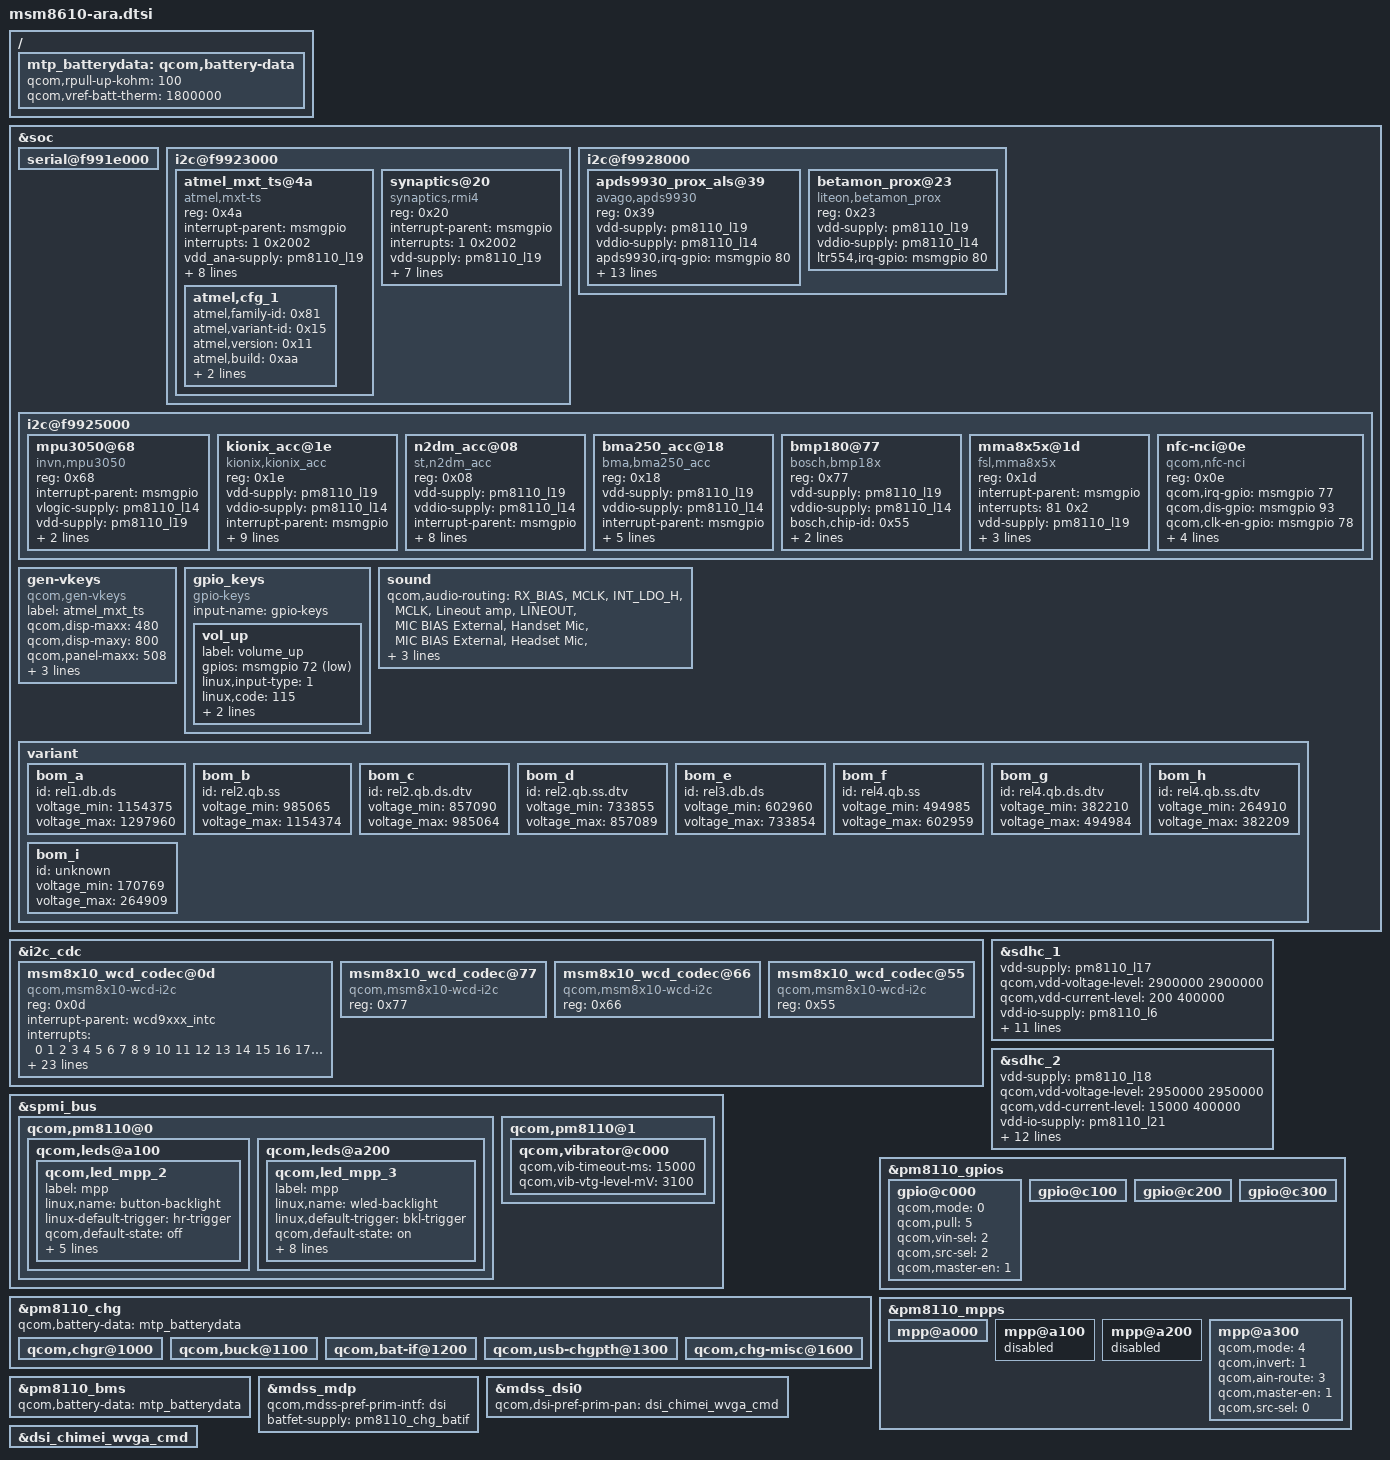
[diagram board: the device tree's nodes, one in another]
/* Copyright (c) 2013-2014, The Linux Foundation. All rights reserved.
 *
 * This program is free software; you can redistribute it and/or modify
 * it under the terms of the GNU General Public License version 2 and
 * only version 2 as published by the Free Software Foundation.
 *
 * This program is distributed in the hope that it will be useful,
 * but WITHOUT ANY WARRANTY; without even the implied warranty of
 * MERCHANTABILITY or FITNESS FOR A PARTICULAR PURPOSE.  See the
 * GNU General Public License for more details.
 */

&soc {
	serial@f991e000 {
		status = "ok";
	};

	i2c@f9923000{
		atmel_mxt_ts@4a {
		compatible = "atmel,mxt-ts";
		reg = <0x4a>;
		interrupt-parent = <&msmgpio>;
		interrupts = <1 0x2002>;
		vdd_ana-supply = <&pm8110_l19>;
		vcc_i2c-supply = <&pm8110_l14>;
		atmel,reset-gpio = <&msmgpio 0 0x00>;
		atmel,irq-gpio = <&msmgpio 1 0x00>;
		atmel,panel-coords = <0 0 508 880>;
		atmel,display-coords = <0 0 480 800>;
		atmel,i2c-pull-up;
		atmel,no-force-update;
		atmel,no-lpm-support;
		atmel,cfg_1 {
			atmel,family-id = <0x81>;
			atmel,variant-id = <0x15>;
			atmel,version = <0x11>;
			atmel,build = <0xaa>;
			atmel,config = [
				/* Object 6, Instance = 0 */
				00 00 00 00 00 00
				/* Object 38, Instance = 0 */
				1d 13 00 17 01 0e 00 00
				/* Object 7, Instance = 0 */
				20 0a 32
				/* Object 8, Instance = 0 */
				19 00 14 14 00 00 ff 00 00 00
				/* Object 9, Instance = 0 */
				83 00 00 13 0b 00 20 32 01 03
				00 0a 05 30 05 05 0a 00 70 03
				fc 01 04 2f f8 dc 00 00 40 00
				00 0a 00 00 02
				/* Object 18, Instance = 0 */
				00 00
				/* Object 19, Instance = 0 */
				00 00 00 00 00 00
				/* Object 25, Instance = 0 */
				03 00 18 79 a8 61
				/* Object 58, Instance = 0 */
				00 00 00 00 00 00 00 00 00 00
				00
				/* Object 42, Instance = 0 */
				03 19 1e 14 80 05 05 00
				/* Object 46, Instance = 0 */
				04 03 08 10 00 00 00 00 00
				/* Object 47, Instance = 0 */
				00 00 00 00 00 00 00 00 00 00
				/* Object 48, Instance = 0 */
				1d c0 22 00 00 00 00 00 00 00
				20 19 00 06 06 00 00 64 04 40
				00 00 00 05 00 2a 00 00 00 19
				34 0c 00 00 00 00 00 00 00 00
				00 00 00 00 00 00 00 00 00 00
				00 00 00 00
				/* Object 55, Instance = 0 */
				00 00 00 00
				];
			};
		};

		synaptics@20 {
			compatible = "synaptics,rmi4";
			reg = <0x20>;
			interrupt-parent = <&msmgpio>;
			interrupts = <1 0x2002>;
			vdd-supply = <&pm8110_l19>;
			vcc_i2c-supply = <&pm8110_l14>;
			synaptics,reset-gpio = <&msmgpio 0 0x00>;
			synaptics,irq-gpio = <&msmgpio 1 0x2008>;
			synaptics,button-map = <139 102 158>;
			synaptics,i2c-pull-up;
			synaptics,power-down;
			synaptics,disable-gpios;
		};
	};

	i2c@f9928000 {
        apds9930_prox_als@39 {
            reg = <0x39>;
            compatible = "avago,apds9930";
            vdd-supply = <&pm8110_l19>;
            vddio-supply = <&pm8110_l14>;
            apds9930,irq-gpio = <&msmgpio 80 0>;
            apds9930,ps_detection_threshold = <708>;
            apds9930,ps_hsythresis_threshold = <458>;
            apds9930,ps_pulse_number = <3>;
            apds9930,ps_pdrive_ma = <0x40>;
            apds9930,ps_pgain = <0x08>;
            apds9930,ps_poffset = <0>;
            apds9930,als_threshold_hsytersis = <20>;
            apds9930,als_use_irq_in_idle = <1>;
            apds9930,als_ga = <2200>;
            apds9930,als_coe_b = <186>;
            apds9930,als_coe_c = <82>;
            apds9930,als_coe_d = <116>;
            apds9930,als_df = <52>;
        };
    };

	i2c@f9925000 {
		mpu3050@68 {
			#address-cells = <1>;
			#size-cells = <0>;
			status = "okay";
			reg = <0x68>;
			compatible = "invn,mpu3050";
			interrupt-parent = <&msmgpio>;
			vlogic-supply = <&pm8110_l14>;
			vdd-supply = <&pm8110_l19>;
			invn,gpio-en = <&pm8110_gpios 2 0x2>;
			invn,poll-interval = <200>;
		};

                kionix_acc@1e {
                        reg = <0x1e>;
                        compatible = "kionix,kionix_acc";
                        vdd-supply = <&pm8110_l19>;
                        vddio-supply = <&pm8110_l14>;
                        interrupt-parent = <&msmgpio>;
                        interrupts = <81 0x2>;
                        kionix_acc,min_interval = <0x5>;
                        kionix_acc,poll_interval = <200>;
                        kionix_acc,accel_direction = <6>;
                        kionix_acc,accel_irq_use_ddtap = <1>;
                        kionix_acc,accel_res = <3>;
                        kionix_acc,accel_g_range = <0>;
                        kionix_acc,accel_tap_z_direction = <1>;
                        kionix_acc,accel_dtap_z_direction = <1>;
                };

                n2dm_acc@08 {
                        reg = <0x08>;
                        compatible = "st,n2dm_acc";
                        vdd-supply = <&pm8110_l19>;
                        vddio-supply = <&pm8110_l14>;
                        interrupt-parent = <&msmgpio>;
                        interrupts = <81 0x2>;
                        n2dm_acc,min_interval = <0x5>;
                        n2dm_acc,poll_interval = <200>;
                        n2dm_acc,accel_direction = <6>;
                        n2dm_acc,accel_irq_use_ddtap = <1>;
                        n2dm_acc,accel_g_range = <0>;
                        n2dm_acc,accel_tap_z_direction = <1>;
                        n2dm_acc,accel_dtap_z_direction = <1>;
                };

                bma250_acc@18 {
                        reg = <0x18>;
                        compatible = "bma,bma250_acc";
                        vdd-supply = <&pm8110_l19>;
                        vddio-supply = <&pm8110_l14>;
                        interrupt-parent = <&msmgpio>;
                        interrupts = <81 0x2>;
                        bma250_acc,min_interval = <0x5>;
                        bma250_acc,poll_interval = <200>;
                        bma250_acc,accel_direction = <6>;
                        bma250_acc,accel_g_range = <3>;
                }; 
		bmp180@77 {
			reg = <0x77>;
			compatible = "bosch,bmp18x";
			vdd-supply = <&pm8110_l19>;
			vddio-supply = <&pm8110_l14>;
			bosch,chip-id = <0x55>;
			bosch,oversample = <3>;
			bosch,period = <1000>;
		};

		mma8x5x@1d {
			reg = <0x1d>;
			compatible = "fsl,mma8x5x";
			interrupt-parent = <&msmgpio>;
			interrupts = <81 0x2>;
			vdd-supply = <&pm8110_l19>;
			vio-supply = <&pm8110_l14>;
			fsl,irq-gpio = <&msmgpio 81 0x00>;
			fsl,sensors-position = <5>;
		};

		nfc-nci@0e {
			compatible = "qcom,nfc-nci";
			reg = <0x0e>;
			qcom,irq-gpio = <&msmgpio 77 0x00>;
			qcom,dis-gpio = <&msmgpio 93 0x00>;
			qcom,clk-en-gpio = <&msmgpio 78 0x00>;
			qcom,clk-src = "GPCLK";
			interrupt-parent = <&msmgpio>;
			interrupts = <77 0>;
			qcom,clk-gpio = <&pm8110_gpios 1 0>;
		};
	};

       i2c@f9928000 {
		betamon_prox@23 {
			reg = <0x23>;
			compatible = "liteon,betamon_prox";
			vdd-supply = <&pm8110_l19>;
			vddio-supply = <&pm8110_l14>;
			ltr554,irq-gpio = <&msmgpio 80 0>;
		};			
	};
	
	gen-vkeys {
		compatible = "qcom,gen-vkeys";
		label = "atmel_mxt_ts";
		qcom,disp-maxx = <480>;
		qcom,disp-maxy = <800>;
		qcom,panel-maxx = <508>;
		qcom,panel-maxy = <880>;
		qcom,key-codes = <158 102 139>;
		qcom,y-offset = <35>;
	};

	gpio_keys {
		compatible = "gpio-keys";
		input-name = "gpio-keys";

		vol_up {
			label = "volume_up";
			gpios = <&msmgpio 72 0x1>;
			linux,input-type = <1>;
			linux,code = <115>;
			gpio-key,wakeup;
			debounce-interval = <15>;
		};
	};

    sound {
        qcom,audio-routing =
            "RX_BIAS", "MCLK",
            "INT_LDO_H", "MCLK",
            "Lineout amp", "LINEOUT",
            "MIC BIAS External", "Handset Mic",
            "MIC BIAS External", "Headset Mic",
            "MIC BIAS External", "Secondary Mic",
            "AMIC1", "MIC BIAS External",
            "AMIC2", "MIC BIAS External",
            "AMIC3", "MIC BIAS External";
    };

	variant {
		bom_a {
			id = "rel1.db.ds";
			voltage_min = <1154375>;
			voltage_max = <1297960>;
		};
		bom_b {
			id = "rel2.qb.ss";
			voltage_min = <985065>;
			voltage_max = <1154374>;
		};
		bom_c {
			id = "rel2.qb.ds.dtv";
			voltage_min = <857090>;
			voltage_max = <985064>;
		};
		bom_d {
			id = "rel2.qb.ss.dtv";
			voltage_min = <733855>;
			voltage_max = <857089>;
		};
		bom_e {
			id = "rel3.db.ds";
			voltage_min = <602960>;
			voltage_max = <733854>;
		};
		bom_f {
			id = "rel4.qb.ss";
			voltage_min = <494985>;
			voltage_max = <602959>;
		};
		bom_g {
			id = "rel4.qb.ds.dtv";
			voltage_min = <382210>;
			voltage_max = <494984>;
		};
		bom_h {
			id = "rel4.qb.ss.dtv";
			voltage_min = <264910>;
			voltage_max = <382209>;
		};
		bom_i {
			id = "unknown";
			voltage_min = <170769>;
			voltage_max = <264909>;
		};
	};
};

&i2c_cdc  {
	msm8x10_wcd_codec@0d{
		compatible = "qcom,msm8x10-wcd-i2c";
		reg = <0x0d>;

		interrupt-parent = <&wcd9xxx_intc>;
		interrupts = <0 1 2 3 4 5 6 7 8 9 10 11 12 13 14 15 16
			      17 18 19 20 21 22 23>;

		cdc-vdda-cp-supply = <&pm8110_s4>;
		qcom,cdc-vdda-cp-voltage = <1800000 2150000>;
		qcom,cdc-vdda-cp-current = <650000>;

		cdc-vdda-h-supply = <&pm8110_l6>;
		qcom,cdc-vdda-h-voltage = <1800000 1800000>;
		qcom,cdc-vdda-h-current = <25000>;

		cdc-vdd-px-supply = <&pm8110_l6>;
		qcom,cdc-vdd-px-voltage = <1800000 1800000>;
		qcom,cdc-vdd-px-current = <10000>;

		cdc-vdd-1p2v-supply = <&pm8110_l4>;
		qcom,cdc-vdd-1p2v-voltage = <1200000 1200000>;
		qcom,cdc-vdd-1p2v-current = <5000>;

		cdc-vdd-mic-bias-supply = <&pm8110_l20>;
		qcom,cdc-vdd-mic-bias-voltage = <3075000 3075000>;
		qcom,cdc-vdd-mic-bias-current = <25000>;

		qcom,cdc-micbias-ldoh-v = <0x3>;
		qcom,cdc-micbias-cfilt-sel = <0x0>;
		qcom,cdc-micbias-cfilt-mv = <2700>;
		qcom,cdc-mclk-clk-rate = <12288000>;

		qcom,cdc-static-supplies = "cdc-vdda-h",
					   "cdc-vdd-px",
					   "cdc-vdd-1p2v";

		qcom,cdc-on-demand-supplies = "cdc-vdda-cp",
					      "cdc-vdd-mic-bias";
	};

	msm8x10_wcd_codec@77{
		compatible = "qcom,msm8x10-wcd-i2c";
		reg = <0x77>;
	};

	msm8x10_wcd_codec@66{
		compatible = "qcom,msm8x10-wcd-i2c";
		reg = <0x66>;
	};

	msm8x10_wcd_codec@55{
		compatible = "qcom,msm8x10-wcd-i2c";
		reg = <0x55>;
	};
};

&spmi_bus {
	qcom,pm8110@0 {
		qcom,leds@a100 {
			status = "okay";
			qcom,led_mpp_2 {
				label = "mpp";
				linux,name = "button-backlight";
				linux-default-trigger = "hr-trigger";
				qcom,default-state = "off";
				qcom,max-current = <40>;
				qcom,id = <6>;
				qcom,source-sel = <1>;
				qcom,mode-ctrl = <0x60>;
				qcom,mode = "manual";
			};
		};

		qcom,leds@a200 {
			status = "okay";
			qcom,led_mpp_3 {
				label = "mpp";
				linux,name = "wled-backlight";
				linux,default-trigger = "bkl-trigger";
				qcom,default-state = "on";
				qcom,max-current = <40>;
				qcom,id = <6>;
				qcom,source-sel = <8>;
				qcom,mode-ctrl = <0x10>;
				qcom,pwm-channel = <0>;
				qcom,pwm-us = <27>;
				qcom,vin-ctrl = <0x03>;
				qcom,mode = "pwm";
			};
		};
	};
};

&spmi_bus {
	qcom,pm8110@1 {
		qcom,vibrator@c000 {
			status = "okay";
			qcom,vib-timeout-ms = <15000>;
			qcom,vib-vtg-level-mV = <3100>;
		};
	};
};

&sdhc_1 {
	vdd-supply = <&pm8110_l17>;
	qcom,vdd-voltage-level = <2900000 2900000>;
	qcom,vdd-current-level = <200 400000>;

	vdd-io-supply = <&pm8110_l6>;
	qcom,vdd-io-always-on;
	qcom,vdd-io-voltage-level = <1800000 1800000>;
	qcom,vdd-io-current-level = <200 60000>;

	qcom,pad-pull-on = <0x0 0x3 0x3>; /* no-pull, pull-up, pull-up */
	qcom,pad-pull-off = <0x0 0x3 0x3>; /* no-pull, pull-up, pull-up */
	qcom,pad-drv-on = <0x4 0x4 0x4>; /* 10mA, 10mA, 10mA */
	qcom,pad-drv-off = <0x0 0x0 0x0>; /* 2mA, 2mA, 2mA */

	qcom,clk-rates = <400000 25000000 50000000 100000000 200000000>;
	qcom,bus-speed-mode = "HS200_1p8v", "DDR_1p8v";
	qcom,nonremovable;

	status = "ok";
};

&sdhc_2 {
	vdd-supply = <&pm8110_l18>;
	qcom,vdd-voltage-level = <2950000 2950000>;
	qcom,vdd-current-level = <15000 400000>;

	vdd-io-supply = <&pm8110_l21>;
	qcom,vdd-io-voltage-level = <1800000 2950000>;
	qcom,vdd-io-current-level = <200 50000>;

	qcom,pad-pull-on = <0x0 0x3 0x3>; /* no-pull, pull-up, pull-up */
	qcom,pad-pull-off = <0x0 0x3 0x3>; /* no-pull, pull-up, pull-up */
	qcom,pad-drv-on = <0x4 0x4 0x4>; /* 10mA, 10mA, 10mA */
	qcom,pad-drv-off = <0x0 0x0 0x0>; /* 2mA, 2mA, 2mA */

	qcom,clk-rates = <400000 25000000 47899152 100000000>;

	#address-cells = <0>;
	interrupt-parent = <&sdhc_2>;
	interrupts = <0 1>;
	#interrupt-cells = <1>;
	interrupt-map-mask = <0xffffffff>;
	interrupt-map = <0 &intc 0 125 0
			1 &intc 0 221 0 >;
	interrupt-names = "hc_irq", "pwr_irq", "status_irq";

	status = "ok";
};

&pm8110_chg {
	status = "ok";

	qcom,chgr@1000 {
		status = "ok";
	};

	qcom,buck@1100 {
		status = "ok";
	};

	qcom,bat-if@1200 {
		status = "ok";
	};

	qcom,usb-chgpth@1300 {
		status = "ok";
	};

	qcom,chg-misc@1600 {
		status = "ok";
	};
};

&pm8110_gpios {
	gpio@c000 { /* GPIO 1 */
		qcom,mode = <0>;		/* QPNP_PIN_MODE_DIG_IN */
		qcom,pull = <5>;		/* QPNP_PIN_PULL_NO */
		qcom,vin-sel = <2>;		/* QPNP_PIN_VIN2 */
		qcom,src-sel = <2>;		/* QPNP_PIN_SEL_FUNC_1 */
		qcom,master-en = <1>;
	};

	gpio@c100 { /* GPIO 2 */
	};

	gpio@c200 { /* GPIO 3 */
	};

	gpio@c300 { /* GPIO 4 */
	};
};

&pm8110_mpps {
	mpp@a000 { /* MPP 1 */
	};

	mpp@a100 { /* MPP 2 */
		status = "disabled";
	};

	mpp@a200 { /* MPP 3 */
		status = "disabled";
	};

	mpp@a300 { /* MPP 4 */
		/* PA_THERM config */
		qcom,mode = <4>; /* AIN input */
		qcom,invert = <1>; /* Enable MPP */
		qcom,ain-route = <3>; /* AMUX 8 */
		qcom,master-en = <1>;
		qcom,src-sel = <0>; /* Function constant */
	};
};

/ {
	mtp_batterydata: qcom,battery-data {
		qcom,rpull-up-kohm = <100>;
		qcom,vref-batt-therm = <1800000>;

		/include/ "batterydata-BV5S-1800mAh.dtsi"
	};
};

&pm8110_bms {
	status = "ok";
	qcom,battery-data = <&mtp_batterydata>;
};

&pm8110_chg {
	qcom,battery-data = <&mtp_batterydata>;
};


&mdss_mdp {
	qcom,mdss-pref-prim-intf = "dsi";
	batfet-supply = <&pm8110_chg_batif>;
};

&mdss_dsi0 {
	qcom,dsi-pref-prim-pan = <&dsi_chimei_wvga_cmd>;
};

&dsi_chimei_wvga_cmd {
	/*qcom,cont-splash-enabled; */
};

